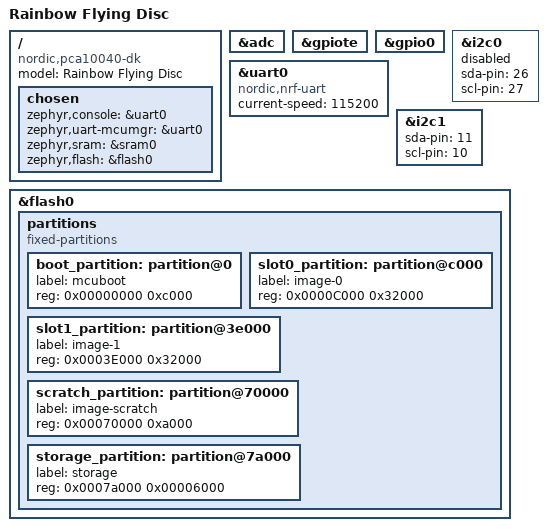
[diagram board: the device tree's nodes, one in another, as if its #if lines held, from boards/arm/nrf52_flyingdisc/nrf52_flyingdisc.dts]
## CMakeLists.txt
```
cmake_minimum_required(VERSION 3.8.2)

# Tell Zephyr where to find the `boards` directory
set(BOARD_ROOT ${CMAKE_CURRENT_LIST_DIR})

# Configure zephyr to use our custom board by default
set(BOARD nrf52_flyingdisc)

# Add our own Kconfig
set(KCONFIG_ROOT ${CMAKE_CURRENT_SOURCE_DIR}/Kconfig)

include($ENV{ZEPHYR_BASE}/cmake/app/boilerplate.cmake NO_POLICY_SCOPE)
project(peripheral)

target_sources(app PRIVATE
  src/main.c
  src/ble.c
  src/pov.c
)

# zephyr_library_include_directories($ENV{ZEPHYR_BASE}/samples/bluetooth)
```

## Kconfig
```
mainmenu "Rainbow Flying Disc Kernel Configuration"

menu "Application"

menu "APA102 Strip Config"
    depends on APA102_STRIP

config APA102_STRIP_NAME
    string
    default "led_strip_apa102"

config APA102_STRIP_BUS_NAME
    string "SPI master to use to drive the strip"
    depends on SPI
    default "SPI_0"
    help
		Specify the device name of the SPI master which the
		APA102 driver should use to control the LED strip.
		Examples: SPI_0, SPI_1, etc.

config APA102_STRIP_FREQUENCY
	int "SPI clock line frequency"
	default 2000000
	help
		SPI clock rate, in Hz, to use while driving the strip.
		The recommended maximum is 2 MHz (2000000); the absolute maximum
		is 20 MHz (20000000). If unsure, accept the default value.

endmenu

endmenu

source "$ZEPHYR_BASE/Kconfig.zephyr"
```

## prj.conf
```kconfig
# Incresed stack due to settings API usage
CONFIG_SYSTEM_WORKQUEUE_STACK_SIZE=2048

CONFIG_BT=y
CONFIG_BT_DEBUG_LOG=y
CONFIG_BT_SMP=y
CONFIG_BT_SIGNING=y
CONFIG_BT_CENTRAL=y
CONFIG_BT_PERIPHERAL=y
CONFIG_BT_GATT_CLIENT=y
CONFIG_BT_ATT_PREPARE_COUNT=2
CONFIG_BT_PRIVACY=y
CONFIG_BT_DEVICE_NAME="Rainbow Flying Disc"
CONFIG_BT_DEVICE_APPEARANCE=833
CONFIG_BT_DEVICE_NAME_DYNAMIC=y
CONFIG_BT_DEVICE_NAME_MAX=65


CONFIG_BT_SETTINGS=y
CONFIG_FLASH=y
CONFIG_FLASH_PAGE_LAYOUT=y
CONFIG_FLASH_MAP=y
CONFIG_FCB=y
CONFIG_SETTINGS=y
CONFIG_SETTINGS_FCB=y

# CONFIG_SENSOR=y

# APA102 LED strip on SPI_0
CONFIG_LED_STRIP=y
CONFIG_APA102_STRIP=y
CONFIG_APA102_STRIP_BUS_NAME="SPI_0"
CONFIG_APA102_STRIP_FREQUENCY=2000000

# CONFIG_I2C=y
# CONFIG_I2C_NRFX=y
# CONFIG_I2C_1_NRF_TWIM=y
# CONFIG_I2C_1=y

# # The IMU attached to I2C_1
# CONFIG_MPU6050=y
# CONFIG_MPU6050_I2C_MASTER_DEV_NAME="I2C_1"
# CONFIG_MPU6050_I2C_ADDR=0x68
# CONFIG_MPU6050_ACCEL_FS=16
# CONFIG_MPU6050_GYRO_FS=2000

# Set optimisations to debug
CONFIG_DEBUG_OPTIMIZATIONS=y

# Allow for a MetaIRQ Coop thread for soley driving the SPI in pov.c
CONFIG_NUM_METAIRQ_PRIORITIES=1
```

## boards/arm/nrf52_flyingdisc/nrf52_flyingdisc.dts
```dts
/dts-v1/;
#include <nordic/nrf52832.dtsi>

/ {
	model = "Rainbow Flying Disc";
	compatible = "nordic,pca10040-dk", "nordic,nrf52832-qfaa",
		     "nordic,nrf52832";

	chosen {
		zephyr,console = &uart0;
#ifdef CONFIG_MCUMGR_SMP_UART
		zephyr,uart-mcumgr = &uart0;
#endif
		zephyr,sram = &sram0;
		zephyr,flash = &flash0;
	};
};

&adc {
	status ="ok";
};

&gpiote {
	status ="ok";
};

&gpio0 {
	status ="ok";
};

&uart0 {
	status = "ok";
	compatible = "nordic,nrf-uart";
	current-speed = <115200>;
};

&i2c0 {
	status = "disable";
	sda-pin = <26>;
	scl-pin = <27>;
};

&i2c1 {
	status = "ok";
	sda-pin = <11>;
	scl-pin = <10>;
};

&flash0 {
	/*
	 * For more information, see:
	 * http://docs.zephyrproject.org/devices/dts/flash_partitions.html
	 */
	partitions {
		compatible = "fixed-partitions";
		#address-cells = <1>;
		#size-cells = <1>;

		boot_partition: partition@0 {
			label = "mcuboot";
			reg = <0x00000000 0xc000>;
		};
		slot0_partition: partition@c000 {
			label = "image-0";
			reg = <0x0000C000 0x32000>;
		};
		slot1_partition: partition@3e000 {
			label = "image-1";
			reg = <0x0003E000 0x32000>;
		};
		scratch_partition: partition@70000 {
			label = "image-scratch";
			reg = <0x00070000 0xa000>;
		};

#if defined(CONFIG_FS_FLASH_STORAGE_PARTITION)
		storage_partition: partition@7a000 {
			label = "storage";
			reg = <0x0007a000 0x00006000>;
		};
#endif
	};
};
```

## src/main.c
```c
/* main.c - Application main entry point */

/*
 * Copyright (c) 2015-2016 Intel Corporation
 *
 * SPDX-License-Identifier: Apache-2.0
 */

// Include generated headerfile for auto completion
#include <autoconf.h>

#include <zephyr/types.h>
#include <stddef.h>
#include <string.h>
#include <errno.h>
#include <misc/printk.h>
#include <misc/byteorder.h>
#include <zephyr.h>

#include <settings/settings.h>

#include <bluetooth/bluetooth.h>
#include <bluetooth/hci.h>
#include <bluetooth/conn.h>
#include <bluetooth/uuid.h>
#include <bluetooth/gatt.h>

#include <board.h>
#include <device.h>
#include <led_strip.h>
#include <gpio.h>
#include <sensor.h>

#include "ble.h"
#include "events.h"
#include "pov.h"

K_MSGQ_DEFINE(events, sizeof(event_t), 10, 4);

static void bt_ready(int err)
{
    if (err) {
        printk("Bluetooth init failed (err %d)\n", err);
        return;
    }

    printk("Bluetooth initialized\n");

    // TODO: Support customising the name per owner?
    // bt_set_name("Rainbow Flying Disc");

    // Initialise and register our Rainbow Flying Disc GATT service
    rainbow_flying_disc_init(&events);

    if (IS_ENABLED(CONFIG_SETTINGS)) {
        settings_load();
    }
}

static void auth_passkey_display(struct bt_conn *conn, unsigned int passkey)
{
    char addr[BT_ADDR_LE_STR_LEN];

    bt_addr_le_to_str(bt_conn_get_dst(conn), addr, sizeof(addr));

    printk("Passkey for %s: %06u\n", addr, passkey);
}

static void auth_cancel(struct bt_conn *conn)
{
    char addr[BT_ADDR_LE_STR_LEN];

    bt_addr_le_to_str(bt_conn_get_dst(conn), addr, sizeof(addr));

    printk("Pairing cancelled: %s\n", addr);
}

static struct bt_conn_auth_cb auth_cb_display = {
    .passkey_display = auth_passkey_display,
    .passkey_entry = NULL,
    .cancel = auth_cancel,
};

void print_mpu_data(struct device *mpu6050) {
    struct sensor_value accel_xyz[3], gyro_xyz[3];

    if(sensor_sample_fetch(mpu6050)) {
        return;
    }

    sensor_channel_get(mpu6050, SENSOR_CHAN_ACCEL_XYZ, accel_xyz);
    sensor_channel_get(mpu6050, SENSOR_CHAN_GYRO_XYZ, gyro_xyz);

    printk("%d.%d\t%d.%d\t%d.%d\t%d\t%d\t%d\n",
        accel_xyz[0].val1, accel_xyz[0].val2,
        accel_xyz[1].val1, accel_xyz[1].val2,
        accel_xyz[2].val1, accel_xyz[2].val2,
        gyro_xyz[0].val1,
        gyro_xyz[1].val1,
        gyro_xyz[2].val1);
}

void main(void)
{
    int err, count = 0;

    struct device *leds = device_get_binding(LED0_GPIO_PORT),
                  *sw0 = device_get_binding(SW0_GPIO_NAME),
                  *sw1 = device_get_binding(SW1_GPIO_NAME);
    // struct device *mpu6050 = device_get_binding(CONFIG_MPU6050_NAME);

    gpio_pin_configure(leds, LED0_GPIO_PIN, GPIO_DIR_OUT);
    gpio_pin_configure(sw0, SW0_GPIO_PIN, GPIO_DIR_IN | SW0_GPIO_PIN_PUD);
    gpio_pin_configure(sw1, SW1_GPIO_PIN, GPIO_DIR_IN | SW1_GPIO_PIN_PUD);


    event_t event_data = {0};

    pov_init();

    err = bt_enable(bt_ready);
    if (err) {
        printk("Bluetooth init failed (err %d)\n", err);
        return;
    }

    // if (mpu6050 == NULL) {
    //     printk("Failed to get IMU driver %s\n", CONFIG_MPU6050_NAME);
    // }

    // TODO: Support a whitelisted mode, only connecting to known devices
    // bt_conn_auth_cb_register(&auth_cb_display);

    while (1) {
        k_sleep(100);

        if (k_msgq_get(&events, &event_data, K_NO_WAIT) == 0)
        {
            switch(event_data.event_type) {
                case kEventMessage:
                    printk("new message event! read %s (%d)\n", event_data.message, event_data.size);
                    pov_set_message(event_data.message, event_data.size);
                    break;
                default:
                    printk("Unhandled event (%d)\n", event_data.event_type);
                    break;
            }
        }

        int sw0_state;
        if(gpio_pin_read(sw0, SW0_GPIO_PIN, &sw0_state) == 0 && sw0_state == 0)
            printk("SW0 is pressed\n");

        int sw1_state;
        if(gpio_pin_read(sw1, SW1_GPIO_PIN, &sw1_state) == 0 && sw1_state == 0)
        {
            printk("SW1 is pressed\n");
            rainbow_flying_disc_discover();
        }

        // if (mpu6050 != NULL)
        //     print_mpu_data(mpu6050); // Test the MPU driver

        gpio_pin_write(leds, LED0_GPIO_PIN, count++ & 0x01);
    }
}
```

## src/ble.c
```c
#include <bluetooth/bluetooth.h>
#include <bluetooth/hci.h>
#include <bluetooth/conn.h>
#include <bluetooth/uuid.h>
#include <bluetooth/gatt.h>

#include "ble.h"
#include "events.h"

#define SCAN_TIMEOUT K_SECONDS(2)
#define MAX_FOUND_DEVICES 10

static enum {
	BLE_DISCONNECTED,
	BLE_SCAN_START,
	BLE_SCAN,
	BLE_CONNECT_CREATE,
	BLE_CONNECT_CANCEL,
	BLE_CONNECTED,
} ble_state;

typedef struct found_device {
    s8_t rssi;
    bt_addr_le_t addr;
} found_device_t;

static struct bt_uuid_128 rfd_service_uuid = BT_UUID_INIT_128(UUID_RAINBOW_FLYING_DISC_SERVICE);
static struct bt_uuid_128 rfd_message_uuid = BT_UUID_INIT_128(UUID_RAINBOW_FLYING_DISC_CHARACTERISTIC_MESSAGE);

static struct bt_gatt_discover_params discov_param;
static struct bt_gatt_read_params read_params;

static u8_t rfd_message[] = { 'R', 'a', 'i', 'n', 'b', 'o', 'w', ' ', 'F', 'l', 'y', 'i', 'n', 'g', ' ', 'D', 'i', 's', 'c'};
static struct {
    found_device_t devices[MAX_FOUND_DEVICES];
    u8_t count;
} found_devices = {0};

static struct k_delayed_work ble_work;
static struct bt_conn *default_conn;
static bool connect_canceled = false;
static u16_t remote_handle;
static bool remote_ready;
static struct k_msgq *_events = NULL;

ssize_t rfd_read_message(struct bt_conn *conn, const struct bt_gatt_attr *attr, void *buf, u16_t len, u16_t offset);
ssize_t rfd_write_message(struct bt_conn *conn, const struct bt_gatt_attr *attr, const void *buf, u16_t len, u16_t offset, u8_t flags);

static void connected(struct bt_conn *conn, u8_t err);
static void disconnected(struct bt_conn *conn, u8_t reason);

// Vendor Primary Service Declaration
static struct bt_gatt_attr vnd_attrs[] = {
    // Vendor Primary Service Declaration
    BT_GATT_PRIMARY_SERVICE(&rfd_service_uuid),
    BT_GATT_CHARACTERISTIC(&rfd_message_uuid.uuid,
        BT_GATT_CHRC_READ | BT_GATT_CHRC_WRITE,
        BT_GATT_PERM_READ_ENCRYPT | BT_GATT_PERM_WRITE_ENCRYPT,
        rfd_read_message,
        rfd_write_message,
        rfd_message),
};

static struct bt_gatt_service vnd_svc = BT_GATT_SERVICE(vnd_attrs);

struct bt_le_scan_param scan_param = {
    .type       = BT_HCI_LE_SCAN_PASSIVE,
    .filter_dup = BT_HCI_LE_SCAN_FILTER_DUP_DISABLE,
    .interval   = 0x0010,
    .window     = 0x0010,
};

static struct bt_conn_cb conn_callbacks = {
	.connected = connected,
	.disconnected = disconnected,
};

ssize_t rfd_read_message(struct bt_conn *conn, const struct bt_gatt_attr *attr, void *buf, u16_t len, u16_t offset)
{
    const char *value = attr->user_data;

    return bt_gatt_attr_read(conn, attr, buf, len, offset, value,
                 strlen(value));
}

ssize_t rfd_write_message(struct bt_conn *conn, const struct bt_gatt_attr *attr, const void *buf, u16_t len, u16_t offset, u8_t flags)
{
    u8_t *value = attr->user_data;

    if (offset + len > sizeof(rfd_message)) {
        return BT_GATT_ERR(BT_ATT_ERR_INVALID_OFFSET);
    }

    memcpy(value + offset, buf, len);

    return len;
}

static bool uuid_match(const u8_t *data, u8_t len, const struct bt_uuid* uuid)
{
    // Loop through each 128-bit UUID and return true on the first match
	while (len >= 16) {
		if (!memcmp(data, BT_UUID_128(uuid)->val, 16)) {
			return true;
		}

		len -= 16;
		data += 16;
	}

	return false;
}

static void create_conn()
{
    if (default_conn || found_devices.count == 0) {
		return;
	}

    // Start with the first device found
    found_device_t *device = &found_devices.devices[0];

    // select the deivce with the highest rssi;
    for(int i = 1; i < found_devices.count; i++)
    {
        if (found_devices.devices[i].rssi > device->rssi)
            device = &found_devices.devices[i];
    }

    char src[BT_ADDR_LE_STR_LEN];
    bt_addr_to_str(&device->addr.a, src, sizeof(src));
    printk("Connecting to [%s]...\n", src);

    default_conn = bt_conn_create_le(&device->addr, BT_LE_CONN_PARAM_DEFAULT);
	if (!default_conn) {
		printk("Failed to initiate connection");
		return;
	}

	ble_state = BLE_CONNECT_CREATE;
	k_delayed_work_submit(&ble_work, SCAN_TIMEOUT);
}

static void connected(struct bt_conn *conn, u8_t err)
{
	struct bt_conn_info info;

	if (err) {
		printk("Connection failed (err %u)\n", err);
		return;
	}

	if (!default_conn) {
		default_conn = bt_conn_ref(conn);
	}

	bt_conn_get_info(conn, &info);
	remote_ready = false;
	remote_handle = 0;

	printk("Connected\n");
	ble_state = BLE_CONNECTED;

	k_delayed_work_submit(&ble_work, K_NO_WAIT);
}

static void disconnected(struct bt_conn *conn, u8_t reason)
{
	printk("Disconnected (reason %u)\n", reason);

	if (default_conn) {
		bt_conn_unref(default_conn);
		default_conn = NULL;
	}

	remote_handle = 0;

	if (ble_state == BLE_CONNECTED) {
		ble_state = BLE_DISCONNECTED;
	}
}

static void device_found(const bt_addr_le_t *addr, s8_t rssi, u8_t type,
			 struct net_buf_simple *ad)
{
	if (type != BT_LE_ADV_IND || found_devices.count >= MAX_FOUND_DEVICES) {
		return;
	}


	while (ad->len > 1) {
		u8_t len = net_buf_simple_pull_u8(ad);
		u8_t type;

		/* Check for early termination */
		if (len == 0) {
			return;
		}

		if (len > ad->len) {
			printk("AD malformed\n");
			return;
		}

		char addr_str[BT_ADDR_LE_STR_LEN];
		bt_addr_to_str(&addr->a, addr_str, sizeof(addr_str));

		type = net_buf_simple_pull_u8(ad);
		if (type == BT_DATA_UUID128_ALL && uuid_match(ad->data, len - 1, &rfd_service_uuid.uuid)) {
			printk("Found device [%s] with RSSI: %ddB\n", addr_str, rssi);

			found_devices.devices[found_devices.count].rssi = rssi;
			memcpy(&found_devices.devices[found_devices.count].addr, addr, sizeof(bt_addr_le_t));
			found_devices.count++;

			return;
		}

		net_buf_simple_pull(ad, len - 1);
	}
}

static u8_t read_message_cb(struct bt_conn *conn, u8_t err, struct bt_gatt_read_params *params, const void *data, u16_t length)
{
    if(data == NULL)
        return BT_GATT_ITER_STOP;

    if(err)
    {
        printk("read_message_cb() read error (%d)", err);
        return BT_GATT_ITER_STOP;
    }

    // queue the received message
    if (event_message(_events, (const char*)data, length, K_NO_WAIT) != 0)
        printk("Could not queue message");

    // Disconnect as we're done.
    // TODO: Where is the best place to disconnect after all read/write operations are done?
    bt_conn_disconnect(default_conn, BT_HCI_ERR_REMOTE_USER_TERM_CONN);

    return BT_GATT_ITER_STOP;
}

static u8_t discover_func(struct bt_conn *conn,
			  const struct bt_gatt_attr *attr,
			  struct bt_gatt_discover_params *param)
{
	int err;

	if (!attr) {
		printk("Discover complete\n");
		memset(&discov_param, 0, sizeof(discov_param));
		return BT_GATT_ITER_STOP;
	}

	printk("Attribute handle %u\n", attr->handle);

	if (param->uuid == &rfd_service_uuid.uuid) {
		printk("Rainbow Flying Disc service discovered\n");
		discov_param.uuid = &rfd_message_uuid.uuid;
		discov_param.start_handle = attr->handle + 1;
		discov_param.type = BT_GATT_DISCOVER_CHARACTERISTIC;

		err = bt_gatt_discover(conn, &discov_param);
		if (err) {
			printk("Char Discovery failed (err %d)\n", err);
		}
	} else if (param->uuid == &rfd_message_uuid.uuid) {
		printk("Message characteristic discovered\n");

		remote_handle = attr->handle + 1;

	} else {
		printk("Uhhh, unknown uuid in dovery callback %s", bt_uuid_str(param->uuid));
	}

	if (remote_handle) {
        // TODO: Read message here?

        read_params.func = read_message_cb;
        read_params.single.handle = remote_handle;
        read_params.single.offset = 0;
        read_params.handle_count = 1;
        bt_gatt_read(conn, &read_params);
	}

	return BT_GATT_ITER_STOP;
}

static void ble_timeout(struct k_work *work)
{
    int err;

    if (connect_canceled) {
		rainbow_flying_disc_cancel_connect();
		return;
	}

	switch (ble_state) {
	    case BLE_DISCONNECTED:
		    break;
	    case BLE_SCAN_START:
            // Reset found devices
            found_devices.count = 0;

            err = bt_le_scan_start(BT_LE_SCAN_PASSIVE, device_found);
            if (err) {
                printk("Scanning failed to start (err %d)\n", err);
            }

            printk("Started scanning for devices\n");
            ble_state = BLE_SCAN;
            k_delayed_work_submit(&ble_work, SCAN_TIMEOUT);
            break;
        case BLE_CONNECT_CREATE:
            printk("Connection attempt timed out\n");
            bt_conn_disconnect(default_conn,
                    BT_HCI_ERR_REMOTE_USER_TERM_CONN);
            ble_state = BLE_SCAN_START;
            k_delayed_work_submit(&ble_work, K_NO_WAIT);
            break;
        case BLE_SCAN:
            bt_le_scan_stop();

            if (found_devices.count == 0) {
                printk("No devices found during scan\n");

                ble_state = BLE_SCAN_START;
                k_delayed_work_submit(&ble_work, K_NO_WAIT);
            } else {
                // Try connecting to the device with the highest RSSI
                create_conn();
            }

            break;
        case BLE_CONNECTED:
            discov_param.uuid = &rfd_service_uuid.uuid;
            discov_param.func = discover_func;
            discov_param.start_handle = 0x0001;
            discov_param.end_handle = 0xffff;
            discov_param.type = BT_GATT_DISCOVER_PRIMARY;

            err = bt_gatt_discover(default_conn, &discov_param);
            if (err) {
                printk("Discover failed (err %d)\n", err);
                return;
            }
            break;
        case BLE_CONNECT_CANCEL:
            break;
	}
}

void rainbow_flying_disc_init(struct k_msgq *events)
{
    _events = events;
    k_delayed_work_init(&ble_work, ble_timeout);

    bt_conn_cb_register(&conn_callbacks);

	bt_gatt_service_register(&vnd_svc);
}

void rainbow_flying_disc_discover()
{
    if (ble_state != BLE_DISCONNECTED) {
		printk("Not ready to connect\n");
		return;
	}

	ble_state = BLE_SCAN_START;
	k_delayed_work_submit(&ble_work, K_NO_WAIT);
}

void rainbow_flying_disc_cancel_connect(void)
{
	printk("rainbow_flying_disc_cancel_connect()\n");

	k_delayed_work_cancel(&ble_work);

	switch (ble_state) {
	case BLE_DISCONNECTED:
		break;
	case BLE_SCAN_START:
		ble_state = BLE_DISCONNECTED;
		break;
	case BLE_SCAN:
		connect_canceled = true;
		k_delayed_work_submit(&ble_work, K_NO_WAIT);
		break;
	case BLE_CONNECT_CREATE:
		ble_state = BLE_CONNECT_CANCEL;
		/* Intentional fall-through */
	case BLE_CONNECTED:
		connect_canceled = true;
		k_delayed_work_submit(&ble_work, K_NO_WAIT);
		break;
	case BLE_CONNECT_CANCEL:
		break;
	}
}
```

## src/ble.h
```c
#ifndef _RAINBOW_FLYING_DISC_BLE_H_
#define _RAINBOW_FLYING_DISC_BLE_H_

#include <kernel.h>
#include <bluetooth/uuid.h>

// d9a204a1-9ca4-41ec-9dd6-526d6c53c7fe
#define UUID_RAINBOW_FLYING_DISC_SERVICE \
    0xfe, 0xc7, 0x53, 0x6c, 0x6d, 0x52, 0xd6, 0x9d, \
    0xec, 0x41, 0xa4, 0x9c, 0xa1, 0x04, 0xa2, 0xd9

// d9a204a2-9ca4-41ec-9dd6-526d6c53c7fe
#define UUID_RAINBOW_FLYING_DISC_CHARACTERISTIC_MESSAGE \
    0xfe, 0xc7, 0x53, 0x6c, 0x6d, 0x52, 0xd6, 0x9d, \
    0xec, 0x41, 0xa4, 0x9c, 0xa2, 0x04, 0xa2,0xd9

#ifdef __cplusplus
extern "C" {
#endif

void rainbow_flying_disc_init(struct k_msgq *events);
void rainbow_flying_disc_discover(void);
void rainbow_flying_disc_cancel_connect(void);

// mbox?
// semaphors?
// callback?

#ifdef __cplusplus
}
#endif

#endif // _RAINBOW_FLYING_DISC_BLE_H_
```

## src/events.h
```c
#ifndef _RAINBOW_FLYING_DISC_EVENTS_H_
#define _RAINBOW_FLYING_DISC_EVENTS_H_

#define MAX_MESSAGE_SIZE 80

typedef enum event_type {
    kEventNone,
    kEventMessage,
} event_type_t;

typedef struct {
    event_type_t event_type;
    ssize_t size;
    union {
        char message[MAX_MESSAGE_SIZE];
    };
} event_t;

static int inline event_message(struct k_msgq *msgq, const char* message, ssize_t length, s32_t timeout)
{
    event_t event = {
        .event_type = kEventMessage,
        .size = length
    };

    memcpy(event.message, message, length);

    return k_msgq_put(msgq, &event, timeout);
}

#endif // _RAINBOW_FLYING_DISC_EVENTS_H_
```

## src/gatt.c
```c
#include <bluetooth/bluetooth.h>
#include <bluetooth/hci.h>
#include <bluetooth/conn.h>
#include <bluetooth/uuid.h>
#include <bluetooth/gatt.h>

#include "gatt.h"

#define SCAN_TIMEOUT K_SECONDS(2)
#define MAX_FOUND_DEVICES 10

static enum {
	BLE_DISCONNECTED,
	BLE_SCAN_START,
	BLE_SCAN,
	BLE_CONNECT_CREATE,
	BLE_CONNECT_CANCEL,
	BLE_ADV_START,
	BLE_ADVERTISING,
	BLE_CONNECTED,
} ble_state;

typedef struct found_device {
    s8_t rssi;
    bt_addr_le_t addr;
} found_device_t;

static struct bt_uuid_128 rfd_service_uuid = BT_UUID_INIT_128(UUID_RAINBOW_FLYING_DISC_SERVICE);
static struct bt_uuid_128 rfd_message_uuid = BT_UUID_INIT_128(UUID_RAINBOW_FLYING_DISC_CHARACTERISTIC_MESSAGE);

static struct bt_gatt_discover_params discov_param;
static struct bt_gatt_read_params read_params;

static u8_t rfd_message[] = { 'R', 'a', 'i', 'n', 'b', 'o', 'w', ' ', 'F', 'l', 'y', 'i', 'n', 'g', ' ', 'D', 'i', 's', 'c'};
static struct {
    found_device_t devices[MAX_FOUND_DEVICES];
    u8_t count;
} found_devices = {0};

static struct k_delayed_work ble_work;
static struct bt_conn *default_conn;
static bool connect_canceled = false;
static u16_t remote_handle;
static bool remote_ready;

ssize_t rfd_read_message(struct bt_conn *conn, const struct bt_gatt_attr *attr, void *buf, u16_t len, u16_t offset);
ssize_t rfd_write_message(struct bt_conn *conn, const struct bt_gatt_attr *attr, const void *buf, u16_t len, u16_t offset, u8_t flags);

static void connected(struct bt_conn *conn, u8_t err);
static void disconnected(struct bt_conn *conn, u8_t reason);

// Vendor Primary Service Declaration
static struct bt_gatt_attr vnd_attrs[] = {
    // Vendor Primary Service Declaration
    BT_GATT_PRIMARY_SERVICE(&rfd_service_uuid),
    BT_GATT_CHARACTERISTIC(&rfd_message_uuid.uuid,
        BT_GATT_CHRC_READ | BT_GATT_CHRC_WRITE,
        BT_GATT_PERM_READ_ENCRYPT | BT_GATT_PERM_WRITE_ENCRYPT,
        rfd_read_message,
        rfd_write_message,
        rfd_message),
};

static struct bt_gatt_service vnd_svc = BT_GATT_SERVICE(vnd_attrs);

static const struct bt_data ad[] = {
    BT_DATA_BYTES(BT_DATA_FLAGS, (BT_LE_AD_GENERAL | BT_LE_AD_NO_BREDR)),
    BT_DATA_BYTES(BT_DATA_UUID128_ALL, UUID_RAINBOW_FLYING_DISC_SERVICE),
};

struct bt_le_scan_param scan_param = {
    .type       = BT_HCI_LE_SCAN_PASSIVE,
    .filter_dup = BT_HCI_LE_SCAN_FILTER_DUP_DISABLE,
    .interval   = 0x0010,
    .window     = 0x0010,
};

static struct bt_conn_cb conn_callbacks = {
	.connected = connected,
	.disconnected = disconnected,
};

ssize_t rfd_read_message(struct bt_conn *conn, const struct bt_gatt_attr *attr, void *buf, u16_t len, u16_t offset)
{
    const char *value = attr->user_data;

    return bt_gatt_attr_read(conn, attr, buf, len, offset, value,
                 strlen(value));
}

ssize_t rfd_write_message(struct bt_conn *conn, const struct bt_gatt_attr *attr, const void *buf, u16_t len, u16_t offset, u8_t flags)
{
    u8_t *value = attr->user_data;

    if (offset + len > sizeof(rfd_message)) {
        return BT_GATT_ERR(BT_ATT_ERR_INVALID_OFFSET);
    }

    memcpy(value + offset, buf, len);

    return len;
}

static bool uuid_match(const u8_t *data, u8_t len, const struct bt_uuid* uuid)
{
    // Loop through each 128-bit UUID and return true on the first match
	while (len >= 16) {
		if (!memcmp(data, BT_UUID_128(uuid)->val, 16)) {
			return true;
		}

		len -= 16;
		data += 16;
	}

	return false;
}

static void create_conn()
{
    if (default_conn || found_devices.count == 0) {
		return;
	}

    // Start with the first device found
    found_device_t *device = &found_devices.devices[0];

    // select the deivce with the highest rssi;
    for(int i = 1; i < found_devices.count; i++)
    {
        if (found_devices.devices[i].rssi > device->rssi)
            device = &found_devices.devices[i];
    }

    char src[BT_ADDR_LE_STR_LEN];
    bt_addr_le_to_str(&device->addr, src, sizeof(src));
    printk("Found [%s], starting connection...\n", src);

    default_conn = bt_conn_create_le(&device->addr, BT_LE_CONN_PARAM_DEFAULT);
	if (!default_conn) {
		printk("Failed to initiate connection");
		return;
	}

	ble_state = BLE_CONNECT_CREATE;
	k_delayed_work_submit(&ble_work, SCAN_TIMEOUT);
}

static void connected(struct bt_conn *conn, u8_t err)
{
	struct bt_conn_info info;

	if (err) {
		printk("Connection failed (err %u)\n", err);
		return;
	}

	if (ble_state == BLE_ADVERTISING) {
		bt_le_adv_stop();
	}

	if (!default_conn) {
		default_conn = bt_conn_ref(conn);
	}

	bt_conn_get_info(conn, &info);
	remote_ready = false;
	remote_handle = 0;

	printk("Connected\n");
	ble_state = BLE_CONNECTED;

	k_delayed_work_submit(&ble_work, K_NO_WAIT);
}

static void disconnected(struct bt_conn *conn, u8_t reason)
{
	printk("Disconnected (reason %u)\n", reason);

	if (default_conn) {
		bt_conn_unref(default_conn);
		default_conn = NULL;
	}

	remote_handle = 0;

	if (ble_state == BLE_CONNECTED) {
		ble_state = BLE_DISCONNECTED;
	}
}

static void device_found(const bt_addr_le_t *addr, s8_t rssi, u8_t type,
			 struct net_buf_simple *ad)
{
	if (type != BT_LE_ADV_IND || found_devices.count >= MAX_FOUND_DEVICES) {
		return;
	}


	while (ad->len > 1) {
		u8_t len = net_buf_simple_pull_u8(ad);
		u8_t type;

		/* Check for early termination */
		if (len == 0) {
			return;
		}

		if (len > ad->len) {
			printk("AD malformed\n");
			return;
		}

		char addr_str[BT_ADDR_LE_STR_LEN];
        bt_addr_le_to_str(addr, addr_str, sizeof(addr_str));

		type = net_buf_simple_pull_u8(ad);
		if (type == BT_DATA_UUID128_ALL && uuid_match(ad->data, len - 1, &rfd_service_uuid.uuid)) {
			printk("Found device [%s] with RSSI: %ddB\n", addr_str, rssi);

			found_devices.devices[found_devices.count].rssi = rssi;
			memcpy(&found_devices.devices[found_devices.count].addr, addr, sizeof(bt_addr_le_t));
			found_devices.count++;

			return;
		}

		net_buf_simple_pull(ad, len - 1);
	}
}

static u8_t read_message_cb(struct bt_conn *conn, u8_t err, struct bt_gatt_read_params *params, const void *data, u16_t length)
{
    if(data == NULL)
        return BT_GATT_ITER_STOP;

    if(err)
    {
        printk("read_message_cb() read error (%d)", err);
        return BT_GATT_ITER_STOP;
    }

    char message[80];
    memset(message, 0, sizeof(message));
    memcpy(message, data, length);

    printk("read_message_cb() read %s (%d)\n", (const char*)message, length);
    for(int i = 0; i < length; i++)
    {
        printk("%02X", *((char*)data + i) & 0xFF);
    }
    printk("\n");

    bt_conn_disconnect(default_conn, BT_HCI_ERR_REMOTE_USER_TERM_CONN);

    return BT_GATT_ITER_STOP;
}

static u8_t discover_func(struct bt_conn *conn,
			  const struct bt_gatt_attr *attr,
			  struct bt_gatt_discover_params *param)
{
	int err;

	if (!attr) {
		printk("Discover complete\n");
		memset(&discov_param, 0, sizeof(discov_param));
		return BT_GATT_ITER_STOP;
	}

	printk("Attribute handle %u\n", attr->handle);

	if (param->uuid == &rfd_service_uuid.uuid) {
		printk("Rainbow Flying Disc service discovered\n");
		discov_param.uuid = &rfd_message_uuid.uuid;
		discov_param.start_handle = attr->handle + 1;
		discov_param.type = BT_GATT_DISCOVER_CHARACTERISTIC;

		err = bt_gatt_discover(conn, &discov_param);
		if (err) {
			printk("Char Discovery failed (err %d)\n", err);
		}
	} else if (param->uuid == &rfd_message_uuid.uuid) {
		printk("Message characteristic discovered\n");

		remote_handle = attr->handle + 1;

	} else {
		printk("Uhhh, unknown uuid in dovery callback %s", bt_uuid_str(param->uuid));
	}

	if (remote_handle) {
        // TODO: Read message here?

        read_params.func = read_message_cb;
        read_params.single.handle = remote_handle;
        read_params.single.offset = 0;
        read_params.handle_count = 1;
        bt_gatt_read(conn, &read_params);
	}

	return BT_GATT_ITER_STOP;
}

static void ble_timeout(struct k_work *work)
{
    int err;

    if (connect_canceled) {
		rainbow_flying_disc_cancel_connect();
		return;
	}

	switch (ble_state) {
	    case BLE_DISCONNECTED:
		    break;
	    case BLE_SCAN_START:
            // Reset found devices
            found_devices.count = 0;

            err = bt_le_scan_start(BT_LE_SCAN_PASSIVE, device_found);
            if (err) {
                printk("Scanning failed to start (err %d)\n", err);
            }

            printk("Started scanning for devices\n");
            ble_state = BLE_SCAN;
            k_delayed_work_submit(&ble_work, SCAN_TIMEOUT);
            break;
        case BLE_CONNECT_CREATE:
            printk("Connection attempt timed out\n");
            bt_conn_disconnect(default_conn,
                    BT_HCI_ERR_REMOTE_USER_TERM_CONN);
            ble_state = BLE_SCAN_START;
            k_delayed_work_submit(&ble_work, K_NO_WAIT);
            break;
        case BLE_SCAN:
            bt_le_scan_stop();

            if (found_devices.count == 0) {
                printk("No devices found during scan\n");

                ble_state = BLE_SCAN_START;
                k_delayed_work_submit(&ble_work, K_NO_WAIT);
            } else {
                // Try connecting to the device with the highest RSSI
                create_conn();
            }

            break;
        case BLE_CONNECTED:
            discov_param.uuid = &rfd_service_uuid.uuid;
            discov_param.func = discover_func;
            discov_param.start_handle = 0x0001;
            discov_param.end_handle = 0xffff;
            discov_param.type = BT_GATT_DISCOVER_PRIMARY;

            err = bt_gatt_discover(default_conn, &discov_param);
            if (err) {
                printk("Discover failed (err %d)\n", err);
                return;
            }
            break;
        case BLE_CONNECT_CANCEL:
            break;
	}
}

void rainbow_flying_disc_init()
{
    k_delayed_work_init(&ble_work, ble_timeout);

    bt_conn_cb_register(&conn_callbacks);

	bt_gatt_service_register(&vnd_svc);
}

void rainbow_flying_disc_discover()
{
    if (ble_state != BLE_DISCONNECTED) {
		printk("Not ready to connect\n");
		return;
	}

	ble_state = BLE_SCAN_START;
	k_delayed_work_submit(&ble_work, K_NO_WAIT);
}

void rainbow_flying_disc_cancel_connect(void)
{
	printk("rainbow_flying_disc_cancel_connect()\n");

	k_delayed_work_cancel(&ble_work);

	switch (ble_state) {
	case BLE_DISCONNECTED:
		break;
	case BLE_SCAN_START:
		ble_state = BLE_DISCONNECTED;
		break;
	case BLE_SCAN:
		connect_canceled = true;
		k_delayed_work_submit(&ble_work, K_NO_WAIT);
		break;
	case BLE_ADV_START:
		ble_state = BLE_DISCONNECTED;
		break;
	case BLE_ADVERTISING:
		connect_canceled = true;
		k_delayed_work_submit(&ble_work, K_NO_WAIT);
		break;
	case BLE_CONNECT_CREATE:
		ble_state = BLE_CONNECT_CANCEL;
		/* Intentional fall-through */
	case BLE_CONNECTED:
		connect_canceled = true;
		k_delayed_work_submit(&ble_work, K_NO_WAIT);
		break;
	case BLE_CONNECT_CANCEL:
		break;
	}
}
```

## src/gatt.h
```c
#ifndef _RAINBOW_FLYING_DISC_GATT_H_
#define _RAINBOW_FLYING_DISC_GATT_H_

#include <bluetooth/uuid.h>

// d9a204a1-9ca4-41ec-9dd6-526d6c53c7fe
#define UUID_RAINBOW_FLYING_DISC_SERVICE \
    0xfe, 0xc7, 0x53, 0x6c, 0x6d, 0x52, 0xd6, 0x9d, \
    0xec, 0x41, 0xa4, 0x9c, 0xa1, 0x04, 0xa2, 0xd9

// d9a204a2-9ca4-41ec-9dd6-526d6c53c7fe
#define UUID_RAINBOW_FLYING_DISC_CHARACTERISTIC_MESSAGE \
    0xfe, 0xc7, 0x53, 0x6c, 0x6d, 0x52, 0xd6, 0x9d, \
    0xec, 0x41, 0xa4, 0x9c, 0xa2, 0x04, 0xa2,0xd9

#ifdef __cplusplus
extern "C" {
#endif

void rainbow_flying_disc_init(void);
void rainbow_flying_disc_discover(void);
void rainbow_flying_disc_cancel_connect(void);

// mbox?
// semaphors?
// callback?

#ifdef __cplusplus
}
#endif

#endif // _RAINBOW_FLYING_DISC_GATT_H_
```

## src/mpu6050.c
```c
/* Basic driver for the MPU6050 IMU
 *
 * Derived from the register map at https://www.invensense.com/wp-content/uploads/2015/02/MPU-6000-Register-Map1.pdf
 */

#include <zephyr.h>
#include <device.h>
#include <i2c.h>
#include <misc/byteorder.h>

#include "mpu6050.h"

#define MPU6050_GYRO_CONFIG 0x1B
#define MPU6050_ACCEL_CONFIG 0x1C
#define MPU6050_DATA_BASE 0x3B
#define MPU6050_PWR_MGMT_1 0x6B
#define MPU6050_WHOAMI 0x75

int mpu6050_init(struct device *i2c, u8_t addr) {
  int err;
  u8_t res;

  // Check that the MPU6050 is working
  err = i2c_reg_read_byte(i2c, addr, MPU6050_WHOAMI, &res);
  if (err) {
    printk("Failed to read mpu6050 identity\n");
    return err;
  }
  if ((res & 0x7E) != 0x68) {
    printk("mpu6050 wmoami check failed\n");
    return 1;
  }

  // 0b00011000 -> FS_SEL=3 -> max range (±2000°/s)
  err = i2c_reg_write_byte(i2c, addr, MPU6050_GYRO_CONFIG, 0x18);
  if (err) {
    printk("Failed to configure gyrpscope\n");
    return err;
  }

  // 0b00011000 -> AFS_SEL=3 -> max range (±16g)
  err = i2c_reg_write_byte(i2c, addr, MPU6050_ACCEL_CONFIG, 0x18);
  if (err) {
    printk("Failed to configure gyrpscope\n");
    return err;
  }

  // 0x00 -> SLEEP=0 -> wake up
  err = i2c_reg_write_byte(i2c, addr, MPU6050_PWR_MGMT_1, 0x00);
  if (err) {
    printk("Failed to wake mpu6050\n");
    return err;
  }

  return 0;
}

int mpu6050_read(struct device *i2c, u8_t addr, struct mpu6050_data *buf) {
  int err;

  err = i2c_burst_read(i2c, addr, MPU6050_DATA_BASE, (u8_t *)buf, sizeof(struct mpu6050_data));

  if (err) {
    printk("Failed to read from mpu6050\n");
    return err;
  }

  buf->x_accel = sys_be16_to_cpu(buf->x_accel);
  buf->y_accel = sys_be16_to_cpu(buf->y_accel);
  buf->z_accel = sys_be16_to_cpu(buf->z_accel);
  buf->temp    = sys_be16_to_cpu(buf->temp);
  buf->x_gyro  = sys_be16_to_cpu(buf->x_gyro);
  buf->y_gyro  = sys_be16_to_cpu(buf->y_gyro);
  buf->z_gyro  = sys_be16_to_cpu(buf->z_gyro);

  return 0;
}
```

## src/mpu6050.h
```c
#include <stdint.h>

struct mpu6050_data {
  int16_t x_accel;
  int16_t y_accel;
  int16_t z_accel;
  int16_t temp;
  int16_t x_gyro;
  int16_t y_gyro;
  int16_t z_gyro;
} __attribute__ ((packed));



int mpu6050_init(struct device *i2c, u8_t addr);
int mpu6050_read(struct device *i2c, u8_t addr, struct mpu6050_data *buf);
```

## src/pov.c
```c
#include <sys/types.h>

#include <autoconf.h>
#include <zephyr.h>
#include <zephyr/types.h>
#include <stddef.h>
#include <string.h>
#include <errno.h>
#include <misc/printk.h>

#include <board.h>
#include <device.h>
#include <led_strip.h>
#include <gpio.h>

#include <nrfx_timer.h>

#include "pov.h"

#if CONFIG_NUM_METAIRQ_PRIORITIES < 1
    #error Need atleast one MetaIRQ priority
#endif

#define POV_TREAD_STACK_SIZE 500
#define POV_TREAD_PRIORITY K_HIGHEST_THREAD_PRIO
#define POV_PIXEL_COLUMNS 36
#define POV_PIXEL_ROWS 8

// Use Timer2 since Timer1 appears to be used by the bluetooth stack
static const nrfx_timer_t kPovTimer = NRFX_TIMER_INSTANCE(2);
// TODO: the rate at which the PoV pixels are rendered. Needs to be dynamicly set based on RPM
static u32_t pov_timer_us = 1000; //Time (in microseconds) between consecutive compare events.

static u32_t pov_timer_ticks;

// A running counter. Will be deprecated
static int count = 0;
// Semaphore used to wake up  the POV_THEAD
static struct k_sem pov_update_sem;

// Our pixel buffer
static struct led_rgb pixels[POV_PIXEL_COLUMNS][POV_PIXEL_ROWS];

static struct device *led_strip = NULL,
                     *leds = NULL;

static void pov_thread(void *, void *, void *);

K_THREAD_STACK_DEFINE(pov_stack_area, POV_TREAD_STACK_SIZE);
struct k_thread pov_thread_data;
k_tid_t pov_thread_id;

void pov_timer_event_handler(nrf_timer_event_t event_type, void* p_context);

/// Wrapper to invoke the nRF5 SDK's timer IRS
ISR_DIRECT_DECLARE(timer2_isr)
{
    nrfx_timer_2_irq_handler();

    ISR_DIRECT_PM();
    return 1;
}

void pov_init()
{
    led_strip = device_get_binding(CONFIG_APA102_STRIP_NAME);
    leds = device_get_binding(LED1_GPIO_PORT);

    memset(pixels, 0, sizeof(pixels));

    k_sem_init(&pov_update_sem, 0, 1);

    // TODO: Remove this. is used for testing purposes only and not intended for final use.
    for(int col = 0; col < POV_PIXEL_COLUMNS; col++) {
        for(int row = 0; row < POV_PIXEL_ROWS; row++) {
            struct led_rgb *pixel = &pixels[col][row];
            pixel->b = col * 7;
            pixel->r = col * 7;
            pixel->g = 0;
        }
    }

    if(leds != NULL)
    {
        gpio_pin_configure(leds, LED1_GPIO_PIN, GPIO_DIR_OUT);
    }

    if(led_strip == NULL)
    {
        printk("Failed to get LED strip driver %s\n", CONFIG_APA102_STRIP_NAME);
    } else {
        led_strip_update_rgb(led_strip, pixels[0], 8);
    }

    nrfx_timer_config_t timer_config = {
        .frequency          = NRF_TIMER_FREQ_8MHz,
        .mode               = NRF_TIMER_MODE_TIMER,
        .bit_width          = NRF_TIMER_BIT_WIDTH_32,
        .interrupt_priority = NRFX_TIMER_DEFAULT_CONFIG_IRQ_PRIORITY,
        .p_context          = NULL
    };

    // Wire up the nordic's timer handler with Zephyr's IRQ vector table through the direct wrapper above.
    IRQ_DIRECT_CONNECT(NRF5_IRQ_TIMER2_IRQn, NRFX_TIMER_DEFAULT_CONFIG_IRQ_PRIORITY, timer2_isr, 0);
    // TODO: not sure if this is required.
    irq_enable(NRF5_IRQ_TIMER2_IRQn);

    // Typical Timer setup
    nrfx_timer_init(&kPovTimer, &timer_config, pov_timer_event_handler);
    pov_timer_ticks = nrfx_timer_us_to_ticks(&kPovTimer, pov_timer_us);

    // Use a compare value to trigger the interrupt
    nrfx_timer_extended_compare(&kPovTimer,
            NRF_TIMER_CC_CHANNEL0,
            pov_timer_ticks,
            NRF_TIMER_SHORT_COMPARE0_CLEAR_MASK,
            true);

    // Create our meta-IRQ thread for handling SPI driver stuff
    pov_thread_id = k_thread_create(
        &pov_thread_data, pov_stack_area,
        K_THREAD_STACK_SIZEOF(pov_stack_area),
        pov_thread,
        NULL, NULL, NULL,
        POV_TREAD_PRIORITY, K_ESSENTIAL, K_NO_WAIT);

    nrfx_timer_enable(&kPovTimer);
}

void pov_set_message(const char *message, ssize_t length)
{
    // TODO: Render the text to the pixel buffer.
}

void pov_set_rpm(u32_t rpm)
{
    // TODO: Divide the RPM into pixel columns and update the timer2 compare value to match

    // pov_timer_ticks = nrf_drv_timer_ms_to_ticks(&kPovTimer, pov_timer_ms);

    // nrf_drv_timer_extended_compare(
    //      &kPovTimer, NRF_TIMER_CC_CHANNEL0, pov_timer_ticks, NRF_TIMER_SHORT_COMPARE0_CLEAR_MASK, true);
}

void pov_timer_event_handler(nrf_timer_event_t event_type, void* p_context) {
    ARG_UNUSED(p_context);

    if (event_type == NRF_TIMER_EVENT_COMPARE0)
        k_sem_give(&pov_update_sem);
}

static void pov_thread(void *_p1, void *_p2, void *_p3)
{
    ARG_UNUSED(_p1); ARG_UNUSED(_p2); ARG_UNUSED(_p3);

    while(1)
    {
        // Wait for the timer interrupt
        k_sem_take(&pov_update_sem, K_FOREVER);

        // TODO: remove thie
        // Flash a LED for debug purposes only
        if(leds != NULL)
            gpio_pin_write(leds, LED1_GPIO_PIN, count++ & 0x01);

        // TODO: don't rely on counter MOD columns, visually glitches when counter overflows.
        // Push out a column of the pixel buffer to the LED strip
        if(led_strip != NULL)
            led_strip_update_rgb(led_strip, pixels[count % POV_PIXEL_COLUMNS], POV_PIXEL_ROWS);
    }
}
```

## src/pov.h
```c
#ifndef _RAINBOW_FLYING_DISC_POV_H_
#define _RAINBOW_FLYING_DISC_POV_H_

#include <zephyr/types.h>

void pov_init(void);
void pov_set_message(const char *message, ssize_t length);
void pov_set_rpm(u32_t rpm);

#endif // _RAINBOW_FLYING_DISC_POV_H_
```
